# STM32WBA52 register map
File version: 0.1
CPU: CM33 r0p1, little endian, MPU, FPU, 4 interrupt priority bits
Registers are 32-bit, read-write, reset 0x0 unless marked. A register's access mark holds for its fields unless they carry their own. Offsets are from the block's base; [hi:lo] are bit positions; {n}, {i} and the like mark numbered series; 'fields as' and 'values as' point back to an identical list.

## HSEM — Hardware semaphore
Base 0x420C1C00
Same registers: SEC_HSEM 0x520C1C00
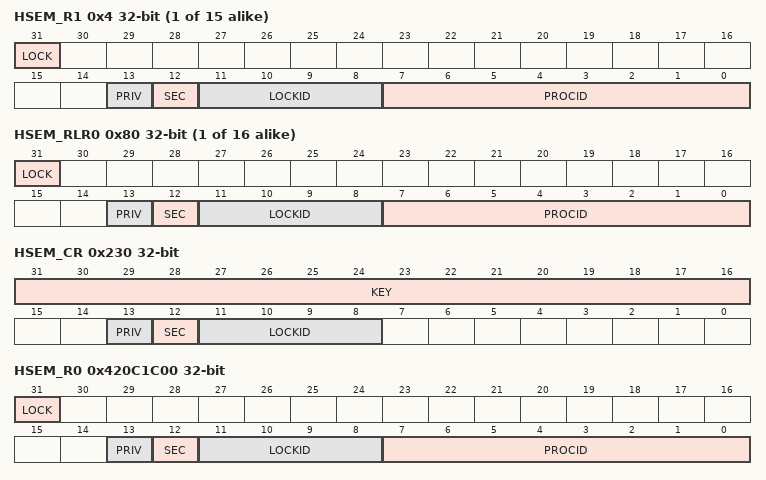
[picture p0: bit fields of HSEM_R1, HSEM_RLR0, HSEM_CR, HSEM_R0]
{0x0+4i} HSEM_R{i} (i=1..15) — HSEM register semaphore {i}
  [31] LOCK — Lock indication This bit can be written and read by software.
    0=On write free semaphore (only when LOCKID and PROCID match), on read semaphore is free; 1=On write try to lock semaphore, on read semaphore is locked
  [13] PRIV — Semaphore privilege Written by software - When the semaphore is free and the LOCK bit is at the same time written to 1, and the LOCKID matches the AHB bus master ID, SEC and PRIV matches the AHB bus master definition. - When the semaphore is unlocked (LOCK written to 0 and AHB bus master ID matched LOCKID, SEC and PRIV matches the AHB bus master definition, the PRIV is cleared to 0. - When the semaphore is unlocked (LOCK bit written to 0 and AHB bus master ID does not match LOCKID and/or SEC or PRIV do not match AHB bus master definition, the PRIV is not affected. - Write when LOCK bit is already 1 (semaphore locked), the PRIV is not affected. - An authorized read returns the stored PRIV value.
    0=Semaphore free or locked by unprivileged compartment; 1=Semaphore locked by privilege compartment
  [12] SEC — Semaphore secure Written by software - When the semaphore is free and the LOCK bit is at the same time written to 1, and the LOCKID matches the AHB bus master ID, SEC and PRIV matches the AHB bus master definition. - When the semaphore is unlocked (LOCK written to 0 and AHB bus master ID matched LOCKID, SEC and PRIV matches the AHB bus master definition, the SEC is cleared to 0. - When the semaphore is unlocked (LOCK bit written to 0 and AHB bus master ID does not match LOCKID and/or SEC or PRIV do not match AHB bus master definition, the SEC is not affected. - Write when LOCK bit is already 1 (semaphore locked), the SEC is not affected. - An authorized read returns the stored SEC value.
    0=Semaphore free or locked by non-secure compartment; 1=Semaphore locked by secure compartment
  [11:8] LOCKID — Semaphore LOCKID Written by software - When the semaphore is free and the LOCK bit is at the same time written to 1 and the LOCKID matches the AHB bus master ID, SEC and PRIV matches the AHB bus master protection. - When the semaphore is unlocked (LOCK written to 0 and AHB bus master ID matched LOCKID, SEC and PRIV matches the AHB bus master protection, the LOCKID is cleared to 0. - When the semaphore is unlocked (LOCK bit written to 0 or AHB bus master ID does not match LOCKID and/or SEC or PRIV do not match AHB bus master protection, the LOCKID is not affected. - Write when LOCK bit is already 1 (semaphore locked), the LOCKID is not affected. - An authorized read returns the stored LOCKID value.
  [7:0] PROCID — Semaphore PROCID Written by software -When the semaphore is free and the LOCK is written to 1, and the LOCKID matches the AHB bus master ID, SEC and PRIV matches the AHB bus master definition, PROCID is set to the written data. - When the semaphore is unlocked, LOCK written to 0 and AHB bus master ID matched LOCKID, SEC and PRIV matches the AHB bus master protection, the PROCID is cleared to 0. - When the semaphore is unlocked, LOCK bit written to 0 and AHB bus master ID does not match LOCKID and/or SEC or PRIV do not match the AHB bus master definition, the PROCID is not affected. - Write when LOCK bit is already 1 (semaphore locked), the PROCID is not affected. - An authorized read returns the stored PROCID value.
{0x80+4i} HSEM_RLR{i} ro (i=0..15) — HSEM read lock register semaphore {i}
  [31] LOCK — Lock indication This bit is read only by software at this address. - When the semaphore is free: A read with a valid AHB bus master ID and SEC and PRIV locks the semaphore and returns 1. - When the semaphore is locked: A read with a valid AHB bus master ID and SEC and PRIV returns 1 (the LOCKID and SEC and PRIV and PROCID reflect the already locked semaphore information).
  [13] PRIV — Semaphore privilege This field is read only by software at this address. - When the semaphore is free: A read with a valid AHB bus master ID and SEC and PRIV locks the semaphore and hardware sets the PRIV to the valid AHB bus master privileged definition. - When the semaphore is locked: A read with a valid AHB bus master ID and SEC and PRIV returns the PRIV of the AHB bus master that has locked the semaphore.
    0=Semaphore free or locked by unprivileged compartment; 1=Semaphore locked by privileged compartment
  [12] SEC — Semaphore secure. This field is read only by software at this address. - When the semaphore is free: A read with a valid AHB bus master ID and SEC and PRIV locks the semaphore and hardware sets the SEC to the valid AHB bus master security definition. - When the semaphore is locked: A read with a valid AHB bus master ID and SEC and PRIV returns the SEC of the AHB bus master that has locked the semaphore.
    values as HSEM_R1.SEC
  [11:8] LOCKID — Semaphore LOCKID This field is read only by software at this address. On a read, when the semaphore is free, the hardware sets the LOCKID to the AHB bus master ID reading the semaphore. The LOCKID of the AHB bus master locking the semaphore is read. On a read when the semaphore is locked, this field returns the LOCKID of the AHB bus master that has locked the semaphore.
  [7:0] PROCID — Semaphore processor ID This field is read only by software at this address. - On a read when the semaphore is free: A read with a valid AHB bus master ID and SEC and PRIV locks the semaphore and hardware sets the PROCID to 0. - When the semaphore is locked: A read with a valid AHB bus master ID and SEC and PRIV returns the PROCID of the AHB bus master that has locked the semaphore.
0x100 HSEM_IER — HSEM non-secure interrupt enable register
  [15:0] ISE — Non-secure Interrupt semaphore x enable bit This bit is read and written by software. When semaphore x SECx is disabled, bit x can be accessed with secure and non-secure access. When semaphore x SECx is enabled, bit x is forced to 0 and cannot be accessed, write to this bit is discarded and a read returns 0. When semaphore x PRIVx is disabled, bit x can be accessed with privilege and unprivileged access. When semaphore x PRIVx is enabled, bit x can be accessed only with privileged access. Unprivileged write to this bit is discarded, unprivileged read returns 0.
    0=Non-secure Interrupt generation for semaphore x disabled (masked); 1=Non-secure Interrupt generation for semaphore x enabled (not masked)
0x104 HSEM_ICR — HSEM non-secure interrupt clear register
  [15:0] ISC — Non-secure Interrupt semaphore x clear bit This bit is written by software, and is always read 0. When semaphore x SECx is disabled, bit x can be accessed with secure and non-secure access. When semaphore x SECx is enabled, bit x cannot be accessed, write to this bit is discarded. When semaphore x PRIVx is disabled, bit x can be accessed with privileged and unprivileged access. When semaphore x PRIVx is enabled, bit x can only be accessed with privileged access. Unprivileged write to this bit is discarded.
    0=non-secure Interrupt semaphore x status ISFx and masked status MISFx not affected; 1=non-secure Interrupt semaphore x status ISFx and masked status MISFx cleared
0x108 HSEM_ISR ro — HSEM non-secure interrupt status register
  [15:0] ISF — Interrupt semaphore x status bit before enable (mask) This bit is set by hardware, and reset only by software. This bit is cleared by software writing the corresponding HSEM_ICR bit.
    0=Interrupt semaphore x status, no interrupt pending; 1=Interrupt semaphore x status, interrupt pending
0x10C HSEM_MISR ro — HSEM non-secure interrupt status register
  [15:0] MISF — Masked non-secure interrupt semaphore x status bit after enable (mask) This bit is set by hardware and read only by software. This bit is cleared by software writing the corresponding HSEM_ICR bit. This bit is read as 0 when semaphore x status is masked in HSEM_IER bit x. When semaphore x SECx is disabled, bit x can be accessed with secure and non-secure access. When semaphore x SECx is enabled, bit x cannot be accessed, read returns 0. When semaphore x PRIVx is disabled, bit x can be accessed with privileged and unprivileged access. When semaphore x PRIVx is enabled, bit x can be accessed only with privileged access. Unprivileged read returns 0.
    0=non-secure interrupt semaphore x status after masking not pending; 1=non-secure interrupt semaphore x status after masking pending
0x180 HSEM_SIER — HSEM secure interrupt enable register
  [15:0] SISE — Secure interrupt semaphore x enable bit This bit is read and written by software. When semaphore x PRIVx is disabled, bit x can be accessed with secure privilege and secure unprivileged access. When semaphore x PRIVx is enabled, bit x can be accessed only with secure privilege access. secure unprivileged write to this bit is discarded, secure unprivileged read return 0 value.
    0=Secure interrupt generation for semaphore x is disabled (masked); 1=Secure interrupt generation for semaphore x is enabled (not masked)
0x184 HSEM_SICR — HSEM secure interrupt clear register
  [15:0] SISC — Secure interrupt semaphore x clear bit This bit is written by software, and is always read 0. When semaphore x PRIVx is disabled, bit x can be accessed with secure privilege and secure unprivileged access. When semaphore x PRIVx is enabled, bit x can be accessed only with secure privilege access. Secure unprivileged write to this bit is discarded.
    0=Secure interrupt semaphore x status ISFx and masked status MISFx not affected; 1=Secure interrupt semaphore x status ISFx and masked status MISFx cleared
0x188 HSEM_SISR ro — HSEM secure interrupt status register
  [15:0] SISF — Secure interrupt semaphore x status bit before enable (mask) This bit is set by hardware and read only by software. Bit is cleared by software writing the corresponding HSEM_SCnICR bit x. When semaphore x PRIVx is disabled, bit x can be accessed with secure privilege and secure unprivileged access. When semaphore x PRIVx is enabled, bit x can be accessed only with secure privilege access. Secure unprivileged read return 0 value.
    0=Secure interrupt semaphore x status, no interrupt pending; 1=Secure interrupt semaphore x status, interrupt pending
0x18C HSEM_MSISR ro — HSEM secure masked interrupt status register
  [15:0] SMISF — Secure masked interrupt semaphore x status bit after enable (mask) This bit is set by hardware and read only by software. Bit is cleared by software writing the corresponding HSEM_SCnICR bit x. Bit is read as 0 when semaphore x status is masked in HSEM_SCnIER bit x. When semaphore x PRIVx is disabled, bit x can be accessed with secure privilege and secure unprivileged access. When semaphore x PRIVx is enabled, bit x can be accessed only with secure privilege access. Secure unprivileged read return 0 value.
    0=Secure interrupt semaphore x status after masking not pending; 1=Secure interrupt semaphore x status after masking pending
0x200 HSEM_SECCFGR — HSEM security configuration register
  [15:0] SEC — Semaphore x security attribute This bit is set and cleared by software.
    0=Semaphore x non-security, can be accessed by both secure and non-secure processors. When unlocking semaphore x both a secure and non-secure interrupt can be generated.; 1=Semaphore x security, can be accessed only by secure processors. When unlocking semaphore x only a secure interrupt can be generated.
0x210 HSEM_PRIVCFGR — HSEM privilege configuration register
  [15:0] PRIV — Semaphore x privilege attribute This bit is set and cleared by software. When semaphore x SECx is disabled, bit x can be write accessed with secure privileged and non-secure privileged access. When semaphore x SECx is enabled, bit x can only be write accessed with secure privilege access. Non-secure privileged write access is discarded. Both secure and non-secure read return the register bit x value
    0=Semaphore x unprivileged, can be accessed by both privileged and unprivileged processors; 1=Semaphore x privileged, can be accessed only by privileged processors
0x230 HSEM_CR wo — HSEM clear register
  [31:16] KEY — Semaphore clear key This field can be written by software and is always read 0. If this key value does not match HSEM_KEYR.KEY, semaphores are not affected. If this key value matches HSEM_KEYR.KEY, all semaphores matching the LOCKID are cleared to the free state.
  [13] PRIV — PRIV value of semaphores to be cleared. This field can be written by software, is always read 0. Indicates the PRIV for which the CID semaphores are cleared when writing the HSEM_CR.
  [12] SEC — SEC value of semaphores to be cleared. This field can be written by software, is always read 0. Indicates the SEC for which the CID semaphores are cleared when writing the HSEM_CR
  [11:8] LOCKID — LOCKID of semaphores to be cleared This field can be written by software and is always read 0. This field indicates the LOCKID for which the semaphores are cleared when writing the HSEM_CR.
0x234 HSEM_KEYR — HSEM interrupt clear register
  [31:16] KEY — Semaphore clear key This field can be written and read by software. Key value to match when clearing semaphores.
0x420C1C00 HSEM_R0 — HSEM register semaphore 0
  fields as HSEM_R1
